# MKE04Z1284 register map
Vendor: Freescale Semiconductor, Inc.; File version: 1.6
CPU: CM0PLUS r0p0, little endian, no MPU, no FPU, 0x2 interrupt priority bits, 0x0 interrupts
Registers are 32-bit, read-write, reset 0x0 unless marked. A register's access mark holds for its fields unless they carry their own. Offsets are from the block's base; [hi:lo] are bit positions; 'fields as' and 'values as' point back to an identical list.

## CRC — Cyclic Redundancy Check
Base 0x40032000; register names take the prefix CRC_
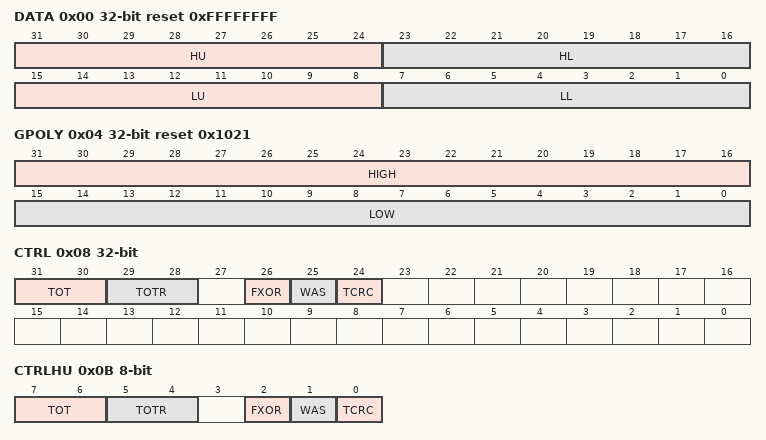
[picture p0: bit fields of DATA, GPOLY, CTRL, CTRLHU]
0x00 DATA reset 0xFFFFFFFF (CRC view) — CRC Data register
  [31:24] HU — CRC High Upper Byte
  [23:16] HL — CRC High Lower Byte
  [15:8] LU — CRC Low Upper Byte
  [7:0] LL — CRC Low Lower Byte
0x00 DATAL 16-bit reset 0xFFFF (CRC view) — CRC_DATAL register.
  [15:0] DATAL — DATAL stores the lower 16 bits of the 16/32 bit CRC
0x00 DATALL 8-bit reset 0xFF (CRC view) — CRC_DATALL register.
  [7:0] DATALL — CRCLL stores the first 8 bits of the 32 bit DATA
0x01 DATALU 8-bit reset 0xFF — CRC_DATALU register.
  [7:0] DATALU — DATALL stores the second 8 bits of the 32 bit CRC
0x02 DATAH 16-bit reset 0xFFFF (CRC view) — CRC_DATAH register.
  [15:0] DATAH — DATAH stores the high 16 bits of the 16/32 bit CRC
0x02 DATAHL 8-bit reset 0xFF (CRC view) — CRC_DATAHL register.
  [7:0] DATAHL — DATAHL stores the third 8 bits of the 32 bit CRC
0x03 DATAHU 8-bit reset 0xFF — CRC_DATAHU register.
  [7:0] DATAHU — DATAHU stores the fourth 8 bits of the 32 bit CRC
0x04 GPOLY reset 0x1021 (CRC view) — CRC Polynomial register
  [31:16] HIGH — High Polynominal Half-word
  [15:0] LOW — Low Polynominal Half-word
0x04 GPOLYL 16-bit reset 0xFFFF (CRC view) — CRC_GPOLYL register.
  [15:0] GPOLYL — POLYL stores the lower 16 bits of the 16/32 bit CRC polynomial value
0x04 GPOLYLL 8-bit reset 0xFF (CRC view) — CRC_GPOLYLL register.
  [7:0] GPOLYLL — POLYLL stores the first 8 bits of the 32 bit CRC
0x05 GPOLYLU 8-bit reset 0xFF — CRC_GPOLYLU register.
  [7:0] GPOLYLU — POLYLL stores the second 8 bits of the 32 bit CRC
0x06 GPOLYH 16-bit reset 0xFFFF (CRC view) — CRC_GPOLYH register.
  [15:0] GPOLYH — POLYH stores the high 16 bits of the 16/32 bit CRC polynomial value
0x06 GPOLYHL 8-bit reset 0xFF (CRC view) — CRC_GPOLYHL register.
  [7:0] GPOLYHL — POLYHL stores the third 8 bits of the 32 bit CRC
0x07 GPOLYHU 8-bit reset 0xFF — CRC_GPOLYHU register.
  [7:0] GPOLYHU — POLYHU stores the fourth 8 bits of the 32 bit CRC
0x08 CTRL — CRC Control register
  [31:30] TOT — Type Of Transpose For Writes
    0=No transposition; 1=Bits in bytes are transposed; bytes are not transposed; 2=Both bits in bytes and bytes are transposed; 3=Only bytes are transposed; no bits in a byte are transposed
  [29:28] TOTR — Type Of Transpose For Read
    values as TOT
  [26] FXOR — Complement Read Of CRC Data Register
    0=No XOR on reading; 1=Invert or complement the read value of the CRC Data register
  [25] WAS — Write CRC Data Register As Seed
    0=Writes to the CRC data register are data values; 1=Writes to the CRC data register are seed values
  [24] TCRC
    0=16-bit CRC protocol; 1=32-bit CRC protocol
0x0B CTRLHU 8-bit — CRC_CTRLHU register.
  [7:6] TOT
    0=No Transposition; 1=Bits in bytes are transposed, bytes are not transposed; 2=Both bits in bytes and bytes are transposed; 3=Only bytes are transposed; no bits in a byte are transposed
  [5:4] TOTR
    values as TOT
  [2] FXOR
    0=No XOR on reading; 1=Invert or complement the read value of CRC data register
  [1] WAS
    0=Writes to CRC data register are data values; 1=Writes to CRC data reguster are seed values
  [0] TCRC
    0=16-bit CRC protocol; 1=32-bit CRC protocol

## PWT — Pulse Width Timer
Base 0x40033000; register names take the prefix PWT_
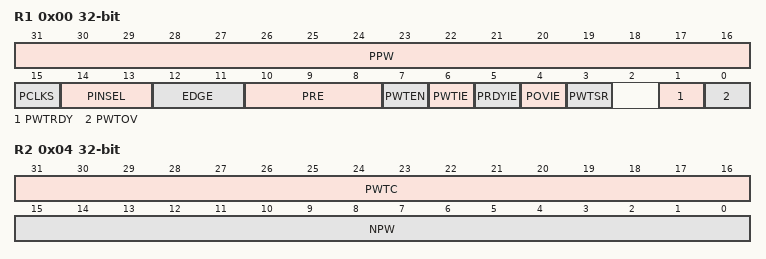
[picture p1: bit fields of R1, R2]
0x00 R1 — Pulse Width Timer Register 1
  [31:16] PPW ro — Positive Pulse Width
  [15] PCLKS — PWT Clock Source Selection
    0=Bus clock is selected as the clock source of PWT counter; 1=Alternative clock is selected as the clock source of PWT counter
  [14:13] PINSEL — PWT Pulse Inputs Selection
    0=PWTIN[0] is enabled; 1=PWTIN[1] is enabled; 2=PWTIN[2] enabled; 3=PWTIN[3] enabled
  [12:11] EDGE — PWT Input Edge Sensitivity
    0=The first falling-edge starts the pulse width measurement, and on all the subsequent falling edges, the pulse width is captured; 1=The first rising edge starts the pulse width measurement, and on all the subsequent rising and falling edges, the pulse width is captured; 2=The first falling edge starts the pulse width measurement, and on all the subsequent rising and falling edges, the pulse width is captured; 3=The first-rising edge starts the pulse width measurement, and on all the subsequent rising edges, the pulse width is captured
  [10:8] PRE — PWT Clock Prescaler (CLKPRE) Setting
    0=Clock divided by 1; 1=Clock divided by 2; 2=Clock divided by 4; 3=Clock divided by 8; 4=Clock divided by 16; 5=Clock divided by 32; 6=Clock divided by 64; 7=Clock divided by 128
  [7] PWTEN — PWT Module Enable
    0=The PWT is disabled; 1=The PWT is enabled
  [6] PWTIE — PWT Module Interrupt Enable
    0=Disables the PWT to generate interrupt; 1=Enables the PWT to generate interrupt
  [5] PRDYIE — PWT Pulse Width Data Ready Interrupt Enable
    0=Disable PWT to generate interrupt when PWTRDY is set; 1=Enable PWT to generate interrupt when PWTRDY is set
  [4] POVIE — PWT Counter Overflow Interrupt Enable
    0=Disable PWT to generate interrupt when PWTOV is set; 1=Enable PWT to generate interrupt when PWTOV is set
  [3] PWTSR wo — PWT Soft Reset
    0=No action taken; 1=Writing 1 to this field will perform soft reset to PWT
  [1] PWTRDY — PWT Pulse Width Valid
    0=PWT pulse width register(s) is not up-to-date; 1=PWT pulse width register(s) has been updated
  [0] PWTOV — PWT Counter Overflow
    0=PWT counter no overflow; 1=PWT counter runs from 0xFFFF to 0x0000
0x04 R2 ro — Pulse Width Timer Register 2
  [31:16] PWTC — PWT Counter. It is suggested to use half-word (16-bit) or word (32-bit) to read out this value.
  [15:0] NPW — Negative Pulse Width. It is suggested to use half-word (16-bit) or word (32-bit) to read out this value.
